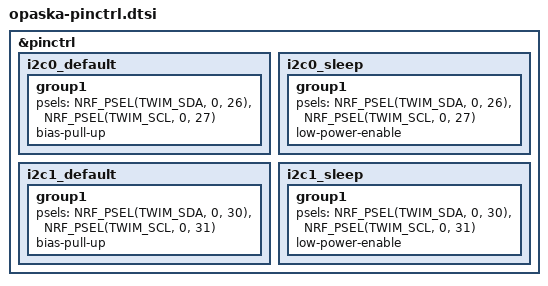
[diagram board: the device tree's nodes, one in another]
#include <zephyr/dt-bindings/pinctrl/nrf-pinctrl.h>

&pinctrl {
	i2c0_default: i2c0_default {
		group1 {
			psels = <NRF_PSEL(TWIM_SDA, 0, 26)>,
				<NRF_PSEL(TWIM_SCL, 0, 27)>;
			bias-pull-up;
		};
	};

	i2c0_sleep: i2c0_sleep {
		group1 {
			psels = <NRF_PSEL(TWIM_SDA, 0, 26)>,
				<NRF_PSEL(TWIM_SCL, 0, 27)>;
			low-power-enable;
		};
	};

	i2c1_default: i2c1_default {
		group1 {
			psels = <NRF_PSEL(TWIM_SDA, 0, 30)>,
				<NRF_PSEL(TWIM_SCL, 0, 31)>;
			bias-pull-up;
		};
	};

	i2c1_sleep: i2c1_sleep {
		group1 {
			psels = <NRF_PSEL(TWIM_SDA, 0, 30)>,
				<NRF_PSEL(TWIM_SCL, 0, 31)>;
			low-power-enable;
		};
	};
};
